# MWPR1516 register map
Vendor: Freescale Semiconductor, Inc.; Series: Kinetis; File version: 1.6
CPU: CM0PLUS r0p0, little endian, no MPU, no FPU, VTOR, 2 interrupt priority bits
Registers are 8-bit, read-write, reset 0x0 unless marked. A register's access mark holds for its fields unless they carry their own. Offsets are from the block's base; [hi:lo] are bit positions; {n}, {i} and the like mark numbered series; 'fields as' and 'values as' point back to an identical list.

## ADC — Analog-to-Digital Converter
Base 0x4003B000; register names take the prefix ADC_
0x00 TIM reset 0x5 — ADC Timing Register
  [6:0] PRS — ADC Clock Prescaler
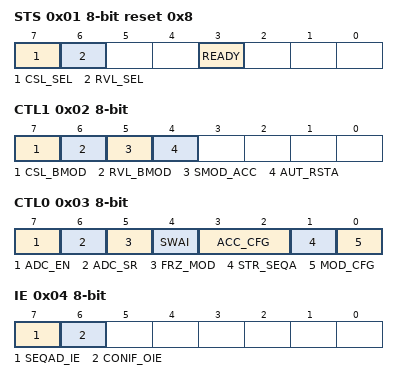
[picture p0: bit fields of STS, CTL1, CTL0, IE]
0x01 STS reset 0x8 — ADC Status Register
  [7] CSL_SEL — Command Sequence List Select bit
    0=ADC Command List 0 is active; 1=ADC Command List 1 is active
  [6] RVL_SEL — Result Value List Select Bit
    0=ADC Result List 0 is active; 1=ADC Result List 1 is active
  [3] READY ro — Ready For Restart Event Flag
    0=ADC not in idle state; 1=ADC is in idle state
0x02 CTL1 — ADC Control Register 1
  [7] CSL_BMOD — CSL Buffer Mode Select Bit
    0=CSL single buffer mode; 1=CSL double buffer mode
  [6] RVL_BMOD — RVL Buffer Mode Select Bit
    0=RVL single buffer mode; 1=RVL double buffer mode
  [5] SMOD_ACC — Special Mode Access Control Bit
    0=Normal user access - Register write restrictions exist as specified for each bit; 1=Special access - Register write restrictions are lifted
  [4] AUT_RSTA — Automatic Restart Event after exit from MCU Stop and Wait Mode (SWAI set)
    0=No automatic restart event after exit from MCU Stop mode; 1=Automatic restart event occurs after exit from MCU Stop mode
0x03 CTL0 — ADC Control Register 0
  [7] ADC_EN — ADC Enable Bit
    0=ADC disabled; 1=ADC enabled
  [6] ADC_SR — ADC Soft-Reset
    0=No ADC Soft-Reset issued; 1=Issue ADC Soft-Reset
  [5] FRZ_MOD — Freeze Mode Configuration
    0=ADC continues conversion in Freeze mode; 1=ADC freezes the conversion at next conversion boundary at Freeze mode entry
  [4] SWAI — Wait Mode Configuration
    0=ADC continues conversion in Wait mode; 1=ADC halts the conversion at next conversion boundary at Wait mode entry
  [3:2] ACC_CFG — ADC_FLWCTL Register Access Configuration
    0=None of the access paths is enabled (default / reset configuration); 1=Single access mode - internal interface(ADC_FLWCTL access via internal interface only); 2=Single access mode - data bus(ADC_FLWCTL access via data bus only); 3=Dual access mode(ADC_FLWCTL register access via internal interface and data bus)
  [1] STR_SEQA — Control Of Conversion Result Storage and RSTAR_EIF flag setting at Sequence Abort or Restart Event
  [0] MOD_CFG — (Conversion Flow Control) Mode Configuration
    0="Restart Mode" selected; 1="Trigger Mode" selected
0x04 IE — ADC Interrupt Enable Register
  [7] SEQAD_IE — Conversion Sequence Abort Done Interrupt Enable Bit
    0=Conversion sequence abort event done interrupt is disabled; 1=Conversion sequence abort event done interrupt is enabled
  [6] CONIF_OIE — ADCCONIF Register Flags Overrun Interrupt Enable
    0=No ADC_CONIF Register Flag overrun is occurred; 1=ADC_CONIF Register Flag overrun is occurred
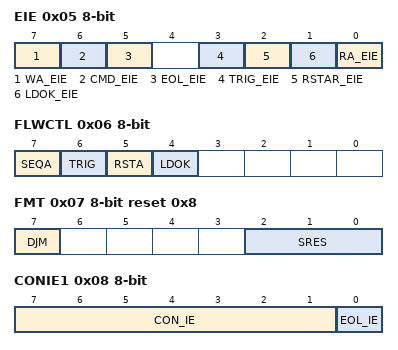
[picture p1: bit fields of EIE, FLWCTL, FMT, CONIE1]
0x05 EIE — ADC Error Interrupt Enable Register
  [7] WA_EIE — Write Access Error Interrupt Enable Bit
    0=Write access error interrupt is disabled; 1=Write access error interrupt is enabled
  [6] CMD_EIE — Command Value Error Interrupt Enable Bit
    0=Command value interrupt is disabled; 1=Command value interrupt is enabled
  [5] EOL_EIE — "End Of List" Error Interrupt Enable Bit
    0="End Of List" error interrupt is disabled; 1="End Of List" error interrupt is enabled
  [3] TRIG_EIE — Conversion Sequence Trigger Error Interrupt Enable Bit
    0=Conversion sequence trigger error interrupt is disabled; 1=Conversion sequence trigger error interrupt is enabled
  [2] RSTAR_EIE — Restart Request Error Interrupt Enable Bit
    0=Restart Request error interrupt is disabled; 1=Restart Request error interrupt is enabled
  [1] LDOK_EIE — Load OK Error Interrupt Enable Bit
    0=Load OK error interrupt is disabled; 1=Load OK error interrupt is enabled
  [0] RA_EIE — Read Access Error Interrupt Enable Bit
    0=Read access error interrupt is disabled; 1=Read access error interrupt is enabled
0x06 FLWCTL — ADC Conversion Flow Control Register
  [7] SEQA — Conversion Sequence Abort Event
    0=No conversion sequence abort request; 1=Conversion sequence abort request
  [6] TRIG — Conversion Sequence Trigger Bit
    0=No conversion sequence trigger; 1=Trigger to start conversion sequence
  [5] RSTA — Restart Event (Restart from Top of Command Sequence List)
    0=Continue with commands from active Sequence Command List; 1=Restart from top of active Sequence Command List
  [4] LDOK — Load OK for alternative Command Sequence List
    0=Load of alternative list done; 1=Load alternative list
0x07 FMT reset 0x8 — ADC Format Register
  [7] DJM — Result Register Data Justification
    0=Left justified data in the conversion result list; 1=Right justified data in the conversion result list
  [2:0] SRES — ADC Resolution Select
    0=8-bit data; 2=10-bit data; 4=12-bit data
0x08 CONIE1 — ADC Conversion Interrupt Enable Register 1
  [7:1] CON_IE — Conversion Interrupt Enable Bits 7:1
    0=ADC conversion interrupt is disabled; 1=ADC conversion interrupt is enabled
  [0] EOL_IE — End Of List Interrupt Enable Bit
    0=End of list interrupt is disabled; 1=End of list interrupt is enabled
0x09 CONIE0 — ADC Conversion Interrupt Enable Register 0
  [7:0] CON_IE — Conversion Interrupt Enable Bits 15:8
    values as CONIE1.CON_IE
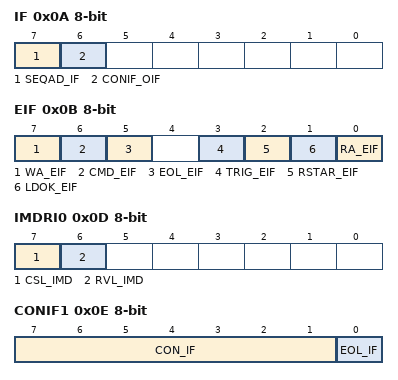
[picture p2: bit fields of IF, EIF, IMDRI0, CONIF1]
0x0A IF — ADC Interrupt Flag Register
  [7] SEQAD_IF — Conversion Sequence Abort Done Interrupt Flag
    0=No conversion sequence abort request occurred; 1=A conversion sequence abort request occurred
  [6] CONIF_OIF — ADCCONIF Register Flags Overrun Interrupt Flag
    0=No ADCCONIF register flag overrun occurred; 1=ADCCONIF register flag overrun occurred
0x0B EIF — ADC Error Interrupt Flag Register
  [7] WA_EIF ro — Write Access Error Interrupt Flag
    0=No write access error occurred; 1=A write access error occurred
  [6] CMD_EIF ro — Command Value Error Interrupt Flag
    0=Valid conversion command is loaded; 1=Invalid conversion command is loaded
  [5] EOL_EIF ro — "End Of List" Error Interrupt Flag
    0=No "End Of List" error; 1="End Of List" command type 'is missing in current executed CSL
  [3] TRIG_EIF ro — Trigger Error Interrupt Flag
    0=No trigger error occurred; 1=A trigger error occurred
  [2] RSTAR_EIF — Restart Request Error Interrupt Flag
    0=No Restart request error situation occurred; 1=Restart request error situation occurred
  [1] LDOK_EIF — Load OK Error Interrupt Flag
    0=No Load OK error situation occurred; 1=Load OK error situation occurred
  [0] RA_EIF ro — Read Access Error Interrupt Flag
    0=No read access error occurred; 1=A read access error occurred
0x0C IMDRI1 ro — ADC Intermediate Result Information Register 1
  [5:0] RIDX_IMD — RES_IDX Value At Intermediate Event
0x0D IMDRI0 ro — ADC Intermediate Result Information Register 0
  [7] CSL_IMD — Active CSL At Intermediate Event
    0=CSL_0 is active (used) when a conversion interrupt flag (CON_IF[15:1]) got set; 1=CSL_1 is active (used) when a conversion interrupt flag (CON_IF[15:1]) got set
  [6] RVL_IMD — Active RVL At Intermediate Event
    0=RVL_0 is active (used) when a conversion interrupt flag (CON_IF[15:1]) got set; 1=RVL_1 is active (used) when a conversion interrupt flag (CON_IF[15:1]) got set
0x0E CONIF1 — ADC Conversion Interrupt Flag Register 1
  [7:1] CON_IF — Conversion Interrupt Flags 7:1
  [0] EOL_IF — End Of List Interrupt Flag
0x0F CONIF0 — ADC Conversion Interrupt Flag Register 0
  [7:0] CON_IF — Conversion Interrupt Flags 15:8
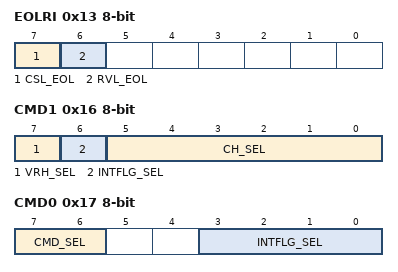
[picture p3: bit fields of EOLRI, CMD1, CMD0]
0x13 EOLRI ro — ADC End Of List Result Information Register
  [7] CSL_EOL — Active CSL When "End Of List" Command Type Executed
    0=CSL_0 is active when "End Of List" command type executed; 1=CSL_1 is active when "End Of List" command type executed
  [6] RVL_EOL — Active RVL When "End Of List" Command Type Executed
    0=RVL_0 is active when "End Of List" command type executed; 1=RVL_1 is active when "End Of List" command type executed
0x15 CMD2 — ADC Command Register 2
  [7:3] SMP — Sample Time Select Bits
    {v}=Sample time in {v+4} ADC clock cycles (v=0..20)
0x16 CMD1 — ADC Command Register 1
  [7] VRH_SEL — Reference High Voltage Select Bit
    0=VRH_0 input is selected as high voltage reference; 1=VRH_1 input is selected as high voltage reference
  [6] INTFLG_SEL — Reference Low Voltage Select Bit
    0=VRL_0 input is selected as low voltage reference; 1=VRL_1 input is selected as low voltage reference
  [5:0] CH_SEL — ADC Input Channel Select Bits
    0=VRL_0/1; 1=VRH_0/1; 2=(VRH_0/1 + VRL_0/1) / 2; 8=Internal_0 (ADC temperature sense); {v}=Internal_{v-8} (v=9..15); 0b01xxxx=ANx. CH_SEL=010000, x=0; CH_SEL=010001, x=1; CH_SEL=011011, x=15, etc
0x17 CMD0 — ADC Command Register 0
  [7:6] CMD_SEL — Conversion Command Select Bits
    0=Normal conversion; 1=End of sequence (wait for trigger to execute next sequence or for a restart); 2=End of list (automatic wrap to top of CSL and continue conversion); 3=End of list (wrap to top of CSL and: in "Restart mode", wait for restart event followed by a trigger; in "Trigger mode", wait for trigger or restart event)
  [3:0] INTFLG_SEL — Conversion Interrupt Flag Select Bits
    0=No flag set; 1=CON_IF[0x0001] is selected; 2=CON_IF[0x0002] is selected; 3=CON_IF[0x0004] is selected; 4=CON_IF[0x0008] is selected; 5=CON_IF[0x0010] is selected; 6=CON_IF[0x0020] is selected; 7=CON_IF[0x0040] is selected; 8=CON_IF[0x0080] is selected; 9=CON_IF[0x0100] is selected; 10=CON_IF[0x0200] is selected; 11=CON_IF[0x0400] is selected; 12=CON_IF[0x0800] is selected; 13=CON_IF[0x1000] is selected; 14=CON_IF[0x2000] is selected; 15=CON_IF[0x4000] is selected
0x1C CBP2 — ADC Command Base Pointer Register 2
  [7:2] CMD_PTR — ADC Command Base Pointer Address [7:2]
0x1D CBP1 — ADC Command Base Pointer Register 1
  [7:0] CMD_PTR — ADC Command Base Pointer Address [15:8]
0x1E CBP0 — ADC Command Base Pointer Register 0
  [7] CMD_PTR — ADC Command Base Pointer Address [23]
0x1F CIDX ro — ADC Command Index Register
  [5:0] CMD_IDX — ADC Command Index Bits
0x20 RBP2 — ADC Result Base Pointer Register 2
  [7:2] RES_PTR — ADC Result Base Pointer Address [7:2]
0x21 RBP1 — ADC Result Base Pointer Register 1
  [7:0] RES_PTR — ADC Result Base Pointer Address [15:8]
0x23 RIDX ro — ADC Result Index Register
  [5:0] RES_IDX — ADC Result Index Bits
0x26 CROFF1 — ADC Command and Result Offset Register 1
  [6:0] CMDRES_OFF1 — ADC Command and Result Offset Value
0x27 CROFF0 ro — ADC Command and Result Offset Register 0
  [6:0] CMDRES_OFF0 — ADC Command and Result Offset Value
